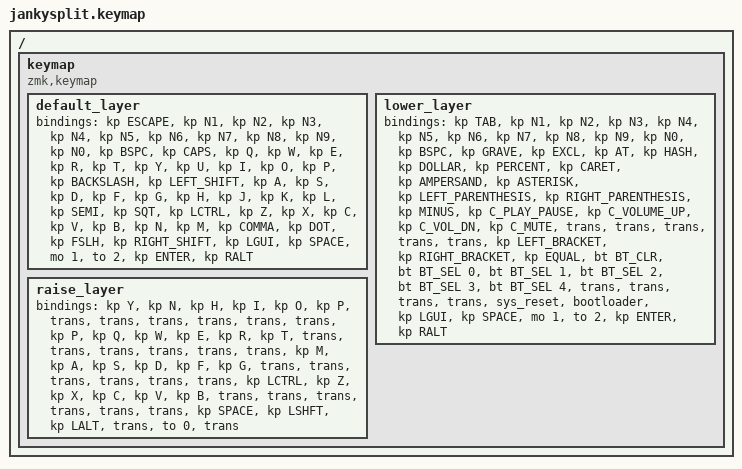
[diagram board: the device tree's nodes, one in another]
#include <behaviors.dtsi>
#include <dt-bindings/zmk/bt.h>
#include <dt-bindings/zmk/keys.h>

/ {
    keymap {
        compatible = "zmk,keymap";

        default_layer {
            // -----------------------------------------------------------------------------------------
            // |  TAB |  1  |  2  |  3  |  4  |  5  |   |  6  |  7  |  8  |  9  |  0  | BSPC |
            // |  TAB |  Q  |  W  |  E  |  R  |  T  |   |  Y  |  U   |  I  |  O  |  P  | BSPC |
            // | CTRL |  A  |  S  |  D  |  F  |  G  |   |  H  |  J   |  K  |  L  |  ;  | BSPC |
            // | SHFT |  Z  |  X  |  C  |  V  |  B  |   |  N  |  M   |  ,  |  .  |  /  | ESC  |
            //                    | GUI | LWR | SPC |   | ENT | RSE  | ALT |

            bindings = <
&kp ESCAPE  &kp N1  &kp N2  &kp N3  &kp N4  &kp N5  &kp N6  &kp N7  &kp N8  &kp N9  &kp N0  &kp BSPC  &kp CAPS  &kp Q  &kp W  &kp E  &kp R  &kp T  &kp Y  &kp U  &kp I  &kp O  &kp P  &kp BACKSLASH  &kp LEFT_SHIFT  &kp A  &kp S  &kp D  &kp F  &kp G  &kp H  &kp J  &kp K  &kp L  &kp SEMI  &kp SQT  &kp LCTRL  &kp Z  &kp X  &kp C  &kp V  &kp B  &kp N  &kp M  &kp COMMA  &kp DOT  &kp FSLH  &kp RIGHT_SHIFT  &kp LGUI  &kp SPACE  &mo 1  &to 2  &kp ENTER  &kp RALT
            >;
        };

        lower_layer {
            // -----------------------------------------------------------------------------------------
            // |  TAB |  1  |  2  |  3  |  4  |  5  |   |  6  |  7  |  8  |  9  |  0  | BSPC |
            // |  TAB |  Q  |  W  |  E  |  R  |  T  |   | BTCLR| BT1 | BT2 | BT3 | BT4 | BT5 |
            // | CTRL |  A  |  S  |  D  |  F  |  G  |   |  H  |  J   |  K  |  L  |  ;  |  '   |
            // | SHFT |  Z  |  X  |  C  |  V  |  B  |   |  N  |  M   |  ,  |  .  |  /  | RST  |
            // | BTCLR| BT1 | BT2 | BT3 | BT4 | BT5 |   |     |      |     |     |     | BOOT |
            //                    | GUI | LWR | SPC |   | ENT | RSE  | ALT |

            bindings = <
&kp TAB  &kp N1  &kp N2  &kp N3  &kp N4  &kp N5  &kp N6  &kp N7  &kp N8  &kp N9  &kp N0  &kp BSPC  &kp GRAVE  &kp EXCL  &kp AT  &kp HASH  &kp DOLLAR  &kp PERCENT  &kp CARET  &kp AMPERSAND  &kp ASTERISK  &kp LEFT_PARENTHESIS  &kp RIGHT_PARENTHESIS  &kp MINUS  &kp C_PLAY_PAUSE  &kp C_VOLUME_UP  &kp C_VOL_DN  &kp C_MUTE  &trans  &trans  &trans  &trans  &trans  &kp LEFT_BRACKET  &kp RIGHT_BRACKET  &kp EQUAL  &bt BT_CLR  &bt BT_SEL 0  &bt BT_SEL 1  &bt BT_SEL 2  &bt BT_SEL 3  &bt BT_SEL 4  &trans  &trans  &trans  &trans  &sys_reset  &bootloader  &kp LGUI  &kp SPACE  &mo 1  &to 2  &kp ENTER  &kp RALT
            >;
        };

        raise_layer {
            bindings = <
&kp Y  &kp N  &kp H  &kp I  &kp O  &kp P  &trans  &trans  &trans  &trans  &trans  &trans  &kp P  &kp Q  &kp W  &kp E  &kp R  &kp T  &trans  &trans  &trans  &trans  &trans  &trans  &kp M  &kp A  &kp S  &kp D  &kp F  &kp G  &trans  &trans  &trans  &trans  &trans  &trans  &kp LCTRL  &kp Z  &kp X  &kp C  &kp V  &kp B  &trans  &trans  &trans  &trans  &trans  &trans  &kp SPACE  &kp LSHFT  &kp LALT  &trans  &to 0  &trans
            >;
        };
    };
};
